# CY8C5268AXI_LP047 register map
File version: 0.1
CY8C52LP
Registers are 8-bit, read-write, no defined reset value unless marked. A register's access mark holds for its fields unless they carry their own. Offsets are from the block's base; lines under a group give offsets from that group; [hi:lo] are bit positions; {n}, {i} and the like mark numbered series; 'fields as' and 'values as' point back to an identical list; <NAME> marks a mode.

## Memory map
0x40004381 SleepTimer size 0x2
0x40004614 BatteryHealth_SAR size 0x158D — SAR ADC
0x400049C8 I2C_Soil size 0x19
0x40006403 I2C_1 size 0x175
0x40006444 Xbee_UART size 0x101 — UART

## SleepTimer
Base 0x40004381
0x00 SleepTimer_CTW_INTERVAL_REG — Timewheel Configuration Register 1
  [3:0] ctw_interval — Sets the central timewheel interval.
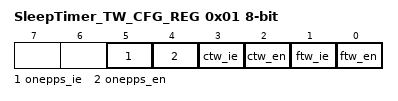
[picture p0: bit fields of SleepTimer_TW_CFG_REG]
0x01 SleepTimer_TW_CFG_REG — Timewheel Configuration Register 2
  [5] onepps_ie — When set and one pulse-per-second is enabled, an interrupt is issued when the pulse occurs.
    1=Enabled (One PPS interrupt is enabled); 0=Disabled (One PPS interrupt is disabled)
  [4] onepps_en — When set, the system returns to the active global power mode once every second.
    1=Enabled (One PPS is enabled); 0=Disabled (One PPS is disabled)
  [3] ctw_ie — When set and the central timewheel is enabled, an interrupt is issued when the central timewheel reaches the selected interval.
    1=Enabled (CTW interrupt is enabled); 0=Disabled (CTW interrupt is disabled)
  [2] ctw_en — When set, the system returns to the active global power mode when the central timewheel reaches the selected interval.
    1=Enabled (CTW is enabled); 0=Disabled (CTW is disabled)
  [1] ftw_ie — When set and the fast timewheel is enabled, an interrupt is issued when it reaches the terminal count.
    1=Enabled (FTW interrupt is enabled); 0=Disabled (FTW interrupt is disabled)
  [0] ftw_en — When set, the system returns to the active global power mode when the fast timewheel reaches the selected interval.
    1=Enabled (FTW is enabled); 0=Disabled (FTW is disabled)

## BatteryHealth_SAR — SAR ADC
Base 0x40004614
0x00 SAR_TR0 — SAR trim register
{0x12EC+i} SAR_CSR{i} (i=0..6) — SAR status and control register {i}
0x150C SAR_SW0 — SAR Analog Routing Register 0
{0x150C+i} SAR_SW{i} (i=2..4) — SAR Analog Routing Register {i}
0x1512 SAR_SW6 — SAR Analog Routing Register 6
0x1513 SAR_CLK — SAR Clock Selection Register
0x158C SAR_WRK 16-bit — SAR working register

## Xbee_UART — UART
Base 0x40006444
0x00 TX_Xbee_UART_TX_DATA — TX Data Register
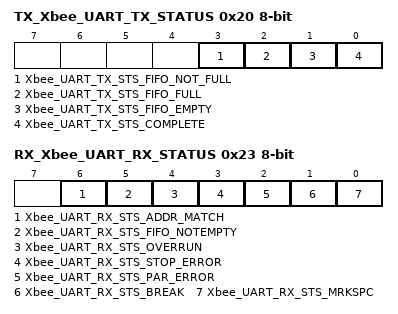
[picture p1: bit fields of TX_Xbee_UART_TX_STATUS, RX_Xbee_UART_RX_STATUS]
0x20 TX_Xbee_UART_TX_STATUS — TX status register
  [3] Xbee_UART_TX_STS_FIFO_NOT_FULL ro, [2] Xbee_UART_TX_STS_FIFO_FULL ro, [1] Xbee_UART_TX_STS_FIFO_EMPTY ro, [0] Xbee_UART_TX_STS_COMPLETE ro
0x23 RX_Xbee_UART_RX_STATUS — RX status register
  [6] Xbee_UART_RX_STS_ADDR_MATCH ro, [5] Xbee_UART_RX_STS_FIFO_NOTEMPTY ro, [4] Xbee_UART_RX_STS_OVERRUN ro, [3] Xbee_UART_RX_STS_STOP_ERROR ro, [2] Xbee_UART_RX_STS_PAR_ERROR ro, [1] Xbee_UART_RX_STS_BREAK ro, [0] Xbee_UART_RX_STS_MRKSPC ro
0xE0 RX_Xbee_UART_RX_ADDRESS1 — RX Address1 Register
0xF0 RX_Xbee_UART_RX_ADDRESS2 — RX Address2 Register
0x100 RX_Xbee_UART_RX_DATA — RX Data Register

## I2C_Soil
Base 0x400049C8
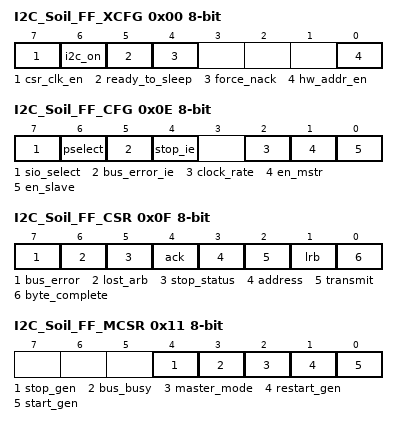
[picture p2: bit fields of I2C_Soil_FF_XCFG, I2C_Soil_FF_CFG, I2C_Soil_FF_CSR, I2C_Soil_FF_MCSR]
0x00 I2C_Soil_FF_XCFG — Extended Configuration Register: I2C_XCFG
  [7] csr_clk_en, [6] i2c_on, [5] ready_to_sleep ro, [4] force_nack, [0] hw_addr_en
0x02 I2C_Soil_FF_ADDR — Slave Adddress Register: I2C_ADR
  [6:0] slave_address — This register holds the slave's 7-bit address.
0x0E I2C_Soil_FF_CFG — Configuration Register: I2C_CFG
  [7] sio_select, [6] pselect, [5] bus_error_ie, [4] stop_ie, [2] clock_rate, [1] en_mstr, [0] en_slave
0x0F I2C_Soil_FF_CSR — Control and Status Register: I2C_CSR
  [7] bus_error, [6] lost_arb, [5] stop_status, [4] ack, [3] address, [2] transmit, [1] lrb, [0] byte_complete
0x10 I2C_Soil_FF_DATA — Data Register: I2C_D
  [7:0] data — This register provides read/write access to the Shift register.
0x11 I2C_Soil_FF_MCSR — Master Control and Status Register: I2C_MCSR
  [4] stop_gen, [3] bus_busy ro, [2] master_mode ro, [1] restart_gen, [0] start_gen
0x13 I2C_Soil_FF__CLK_DIV1 — Divider of BUS_CLK low part: I2C_CLK_DIV1
  [7:0] Div
0x14 I2C_Soil_FF__CLK_DIV2 — Divider high part: I2C_CLK_DIV1
  [1:0] Div
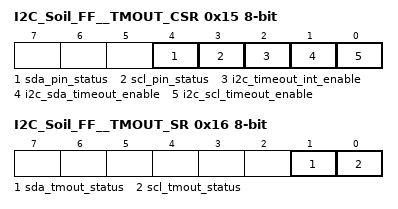
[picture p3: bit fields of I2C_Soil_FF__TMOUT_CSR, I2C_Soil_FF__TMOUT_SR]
0x15 I2C_Soil_FF__TMOUT_CSR — Extended Configuration Register: I2C_TMOUT_CSR
  [4] sda_pin_status, [3] scl_pin_status, [2] i2c_timeout_int_enable ro, [1] i2c_sda_timeout_enable, [0] i2c_scl_timeout_enable
0x16 I2C_Soil_FF__TMOUT_SR — Extended Configuration Register: I2C_TMOUT_SR
  [1] sda_tmout_status, [0] scl_tmout_status
0x17 I2C_Soil_FF__TMOUT_CFG0 — Extended Configuration Register: TMOUT_CFG0
  [7:0] timeout_period_lowbyte
0x18 I2C_Soil_FF__TMOUT_CFG1 — Extended Configuration Register: TMOUT_CFG1
  [3:0] timeout_period_highnibble

## I2C_1
Base 0x40006403
0x00 I2C_1_UDB_MSTR_DATA — Data
  [7:0] data — This register provides read/write access to the Shift register.
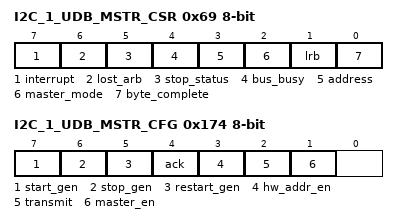
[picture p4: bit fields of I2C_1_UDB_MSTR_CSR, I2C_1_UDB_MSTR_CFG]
0x69 I2C_1_UDB_MSTR_CSR — Status Register
  [7] interrupt ro — Interrupt bit
  [6] lost_arb ro
  [5] stop_status
  [4] bus_busy ro
  [3] address ro
  [2] master_mode ro
  [1] lrb ro
  [0] byte_complete ro
0x89 I2C_1_UDB_MSTR_INT_MASK — Interrupt Mask
0x174 I2C_1_UDB_MSTR_CFG — Configuration Register
  [7] start_gen, [6] stop_gen, [5] restart_gen, [4] ack, [3] hw_addr_en, [2] transmit, [1] master_en
